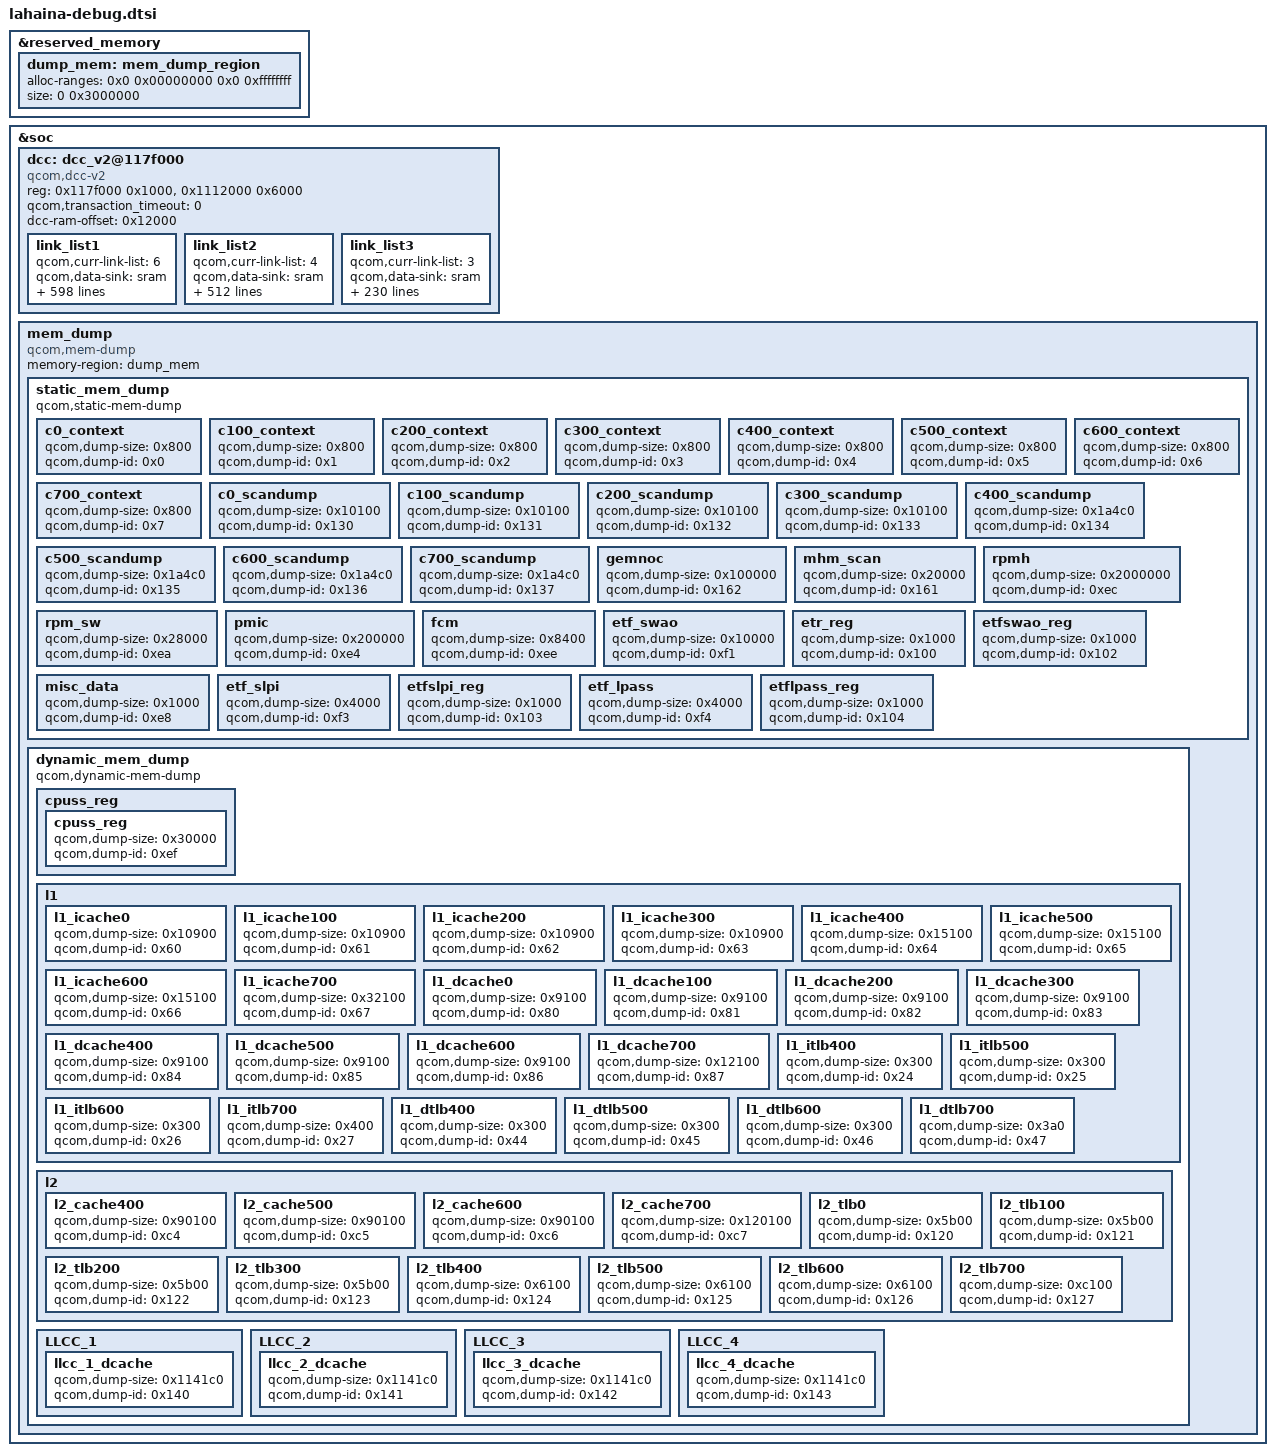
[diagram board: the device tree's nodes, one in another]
// SPDX-License-Identifier: BSD-3-Clause
/*
 * Copyright (c) Qualcomm Technologies, Inc. and/or its subsidiaries.
 */

#include <dt-bindings/soc/qcom,dcc_v2.h>

&reserved_memory {
	#address-cells = <2>;
	#size-cells = <2>;
	ranges;

	dump_mem: mem_dump_region {
		alloc-ranges = <0x0 0x00000000 0x0 0xffffffff>;
		size = <0 0x3000000>;
	};
};

&soc {
	dcc: dcc_v2@117f000 {
		compatible = "qcom,dcc-v2";

		reg = <0x117f000 0x1000>,
			<0x1112000 0x6000>;

		qcom,transaction_timeout = <0>;

		reg-names = "dcc-base", "dcc-ram-base";
		dcc-ram-offset = <0x12000>;

		link_list1 {
			qcom,curr-link-list = <6>;
			qcom,data-sink = "sram";

			qcom,link-list = <DCC_WRITE 0x18080010 0x1 0>,
				<DCC_READ 0x00144018 1 0>,
				<DCC_WRITE 0x00144018 0x1 0>,
				<DCC_READ 0x00144018 1 0>,
				<DCC_READ 0x091a9020 1 0>,
				<DCC_READ_WRITE 0x5 0x1 0>,
				<DCC_READ 0x09102008 1 0>,
				<DCC_READ_WRITE 0x2 0x2 0>,
				<DCC_READ 0x09142008 1 0>,
				<DCC_READ_WRITE 0x2 0x2 0>,
				<DCC_READ 0x09102408 1 0>,
				<DCC_READ_WRITE 0x2 0x2 0>,
				<DCC_READ 0x09142408 1 0>,
				<DCC_READ_WRITE 0x2 0x2 0>,
				<DCC_READ 0x09103808 1 0>,
				<DCC_LOOP 3 0 0>,
				<DCC_READ 0x09103810 1 0>,
				<DCC_READ 0x09103814 1 0>,
				<DCC_LOOP 1 0 0>,
				<DCC_READ 0x09103888 1 0>,
				<DCC_LOOP 2 0 0>,
				<DCC_READ 0x09103890 1 0>,
				<DCC_READ 0x09103894 1 0>,
				<DCC_LOOP 1 0 0>,
				<DCC_READ 0x09143808 1 0>,
				<DCC_LOOP 3 0 0>,
				<DCC_READ 0x09143810 1 0>,
				<DCC_READ 0x09143814 1 0>,
				<DCC_LOOP 1 0 0>,
				<DCC_READ 0x09143888 1 0>,
				<DCC_LOOP 2 0 0>,
				<DCC_READ 0x09143890 1 0>,
				<DCC_READ 0x09143894 1 0>,
				<DCC_LOOP 1 0 0>,
				<DCC_READ 0x09182808 1 0>,
				<DCC_LOOP 2 0 0>,
				<DCC_READ 0x09182810 1 0>,
				<DCC_READ 0x09182814 1 0>,
				<DCC_LOOP 1 0 0>,
				<DCC_READ 0x09182888 1 0>,
				<DCC_LOOP 3 0 0>,
				<DCC_READ 0x09182890 1 0>,
				<DCC_READ 0x09182894 1 0>,
				<DCC_LOOP 1 0 0>,
				<DCC_READ 0x09103008 1 0>,
				<DCC_READ 0x0910300c 1 0>,
				<DCC_WRITE 0x09103028 0x00000001 1>,
				<DCC_LOOP 41 0 0>,
				<DCC_READ 0x09103010 1 0>,
				<DCC_READ 0x09103014 1 0>,
				<DCC_LOOP 1 0 0>,
				<DCC_READ 0x09103408 1 0>,
				<DCC_READ 0x0910340c 1 0>,
				<DCC_WRITE 0x09103428 0x00000001 1>,
				<DCC_LOOP 41 0 0>,
				<DCC_READ 0x09103410 1 0>,
				<DCC_READ 0x09103414 1 0>,
				<DCC_LOOP 1 0 0>,
				<DCC_READ 0x09143008 1 0>,
				<DCC_READ 0x0914300c 1 0>,
				<DCC_WRITE 0x09143028 0x00000001 1>,
				<DCC_LOOP 41 0 0>,
				<DCC_READ 0x09143010 1 0>,
				<DCC_READ 0x09143014 1 0>,
				<DCC_LOOP 1 0 0>,
				<DCC_READ 0x09143408 1 0>,
				<DCC_READ 0x0914340c 1 0>,
				<DCC_WRITE 0x09143428 0x00000001 1>,
				<DCC_LOOP 41 0 0>,
				<DCC_READ 0x09143410 1 0>,
				<DCC_READ 0x09143414 1 0>,
				<DCC_LOOP 1 0 0>,
				<DCC_READ 0x09182008 1 0>,
				<DCC_READ 0x0918200c 1 0>,
				<DCC_WRITE 0x09182028 0x00000001 1>,
				<DCC_LOOP 11 0 0>,
				<DCC_READ 0x09182010 1 0>,
				<DCC_READ 0x09182014 1 0>,
				<DCC_LOOP 1 0 0>,
				<DCC_READ 0x09182408 1 0>,
				<DCC_READ 0x0918240c 1 0>,
				<DCC_WRITE 0x09182428 0x00000001 1>,
				<DCC_LOOP 11 0 0>,
				<DCC_READ 0x09182410 1 0>,
				<DCC_READ 0x09182414 1 0>,
				<DCC_LOOP 1 0 0>,
				<DCC_READ 0x18000024 1 0>,
				<DCC_READ 0x18000040 4 0>,
				<DCC_READ 0x18010024 1 0>,
				<DCC_READ 0x18010040 4 0>,
				<DCC_READ 0x18020024 1 0>,
				<DCC_READ 0x18020040 4 0>,
				<DCC_READ 0x18030024 1 0>,
				<DCC_READ 0x18030040 4 0>,
				<DCC_READ 0x18040024 1 0>,
				<DCC_READ 0x18040040 4 0>,
				<DCC_READ 0x18050024 1 0>,
				<DCC_READ 0x18050040 4 0>,
				<DCC_READ 0x18060024 1 0>,
				<DCC_READ 0x18060040 4 0>,
				<DCC_READ 0x18070024 1 0>,
				<DCC_READ 0x18070040 4 0>,
				<DCC_READ 0x18080024 1 0>,
				<DCC_READ 0x18080040 3 0>,
				<DCC_READ 0x180800f8 1 0>,
				<DCC_READ 0x18080104 1 0>,
				<DCC_READ 0x1808011c 1 0>,
				<DCC_READ 0x18080128 1 0>,
				<DCC_READ 0x18080168 1 0>,
				<DCC_READ 0x18080198 1 0>,
				<DCC_READ 0x9050078 1 0>,
				<DCC_READ 0x9050110 8 0>,
				<DCC_READ 0x9080058 2 0>,
				<DCC_READ 0x90800c8 1 0>,
				<DCC_READ 0x90800d4 1 0>,
				<DCC_READ 0x90800e0 1 0>,
				<DCC_READ 0x90800ec 1 0>,
				<DCC_READ 0x90800f8 1 0>,
				<DCC_READ 0x9084030 1 0>,
				<DCC_READ 0x9084038 2 0>,
				<DCC_READ 0x90840e4 1 0>,
				<DCC_READ 0x90840f4 1 0>,
				<DCC_READ 0x9084104 2 0>,
				<DCC_READ 0x9084194 1 0>,
				<DCC_READ 0x9084804 1 0>,
				<DCC_READ 0x908480c 1 0>,
				<DCC_READ 0x9084844 1 0>,
				<DCC_READ 0x9084850 2 0>,
				<DCC_READ 0x9084860 3 0>,
				<DCC_READ 0x9084888 1 0>,
				<DCC_READ 0x908488c 1 0>,
				<DCC_READ 0x9084900 1 0>,
				<DCC_READ 0x908409c 1 0>,
				<DCC_READ 0x90840a0 1 0>,
				<DCC_READ 0x908426c 1 0>,
				<DCC_READ 0x908439c 1 0>,
				<DCC_READ 0x9085124 1 0>,
				<DCC_READ 0x90ba280 1 0>,
				<DCC_READ 0x90ba288 7 0>,
				<DCC_READ 0x9258610 4 0>,
				<DCC_READ 0x92d8610 4 0>,
				<DCC_READ 0x9358610 4 0>,
				<DCC_READ 0x93d8610 4 0>,
				<DCC_READ 0x9220344 8 0>,
				<DCC_READ 0x9220370 6 0>,
				<DCC_READ 0x9220480 1 0>,
				<DCC_READ 0x9222400 1 0>,
				<DCC_READ 0x922240c 1 0>,
				<DCC_READ 0x9223214 2 0>,
				<DCC_READ 0x9223220 3 0>,
				<DCC_READ 0x9223308 1 0>,
				<DCC_READ 0x9223318 1 0>,
				<DCC_READ 0x9232100 1 0>,
				<DCC_READ 0x9236040 6 0>,
				<DCC_READ 0x92360b0 1 0>,
				<DCC_READ 0x923a004 4 0>,
				<DCC_READ 0x923e030 2 0>,
				<DCC_READ 0x9241000 1 0>,
				<DCC_READ 0x9242028 1 0>,
				<DCC_READ 0x9242044 3 0>,
				<DCC_READ 0x9242070 1 0>,
				<DCC_READ 0x9248030 1 0>,
				<DCC_READ 0x9248048 8 0>,
				<DCC_READ 0x92a0344 8 0>,
				<DCC_READ 0x92a0370 6 0>,
				<DCC_READ 0x92a0480 1 0>,
				<DCC_READ 0x92a2400 1 0>,
				<DCC_READ 0x92a240c 1 0>,
				<DCC_READ 0x92a3214 2 0>,
				<DCC_READ 0x92a3220 3 0>,
				<DCC_READ 0x92a3308 1 0>,
				<DCC_READ 0x92a3318 1 0>,
				<DCC_READ 0x92b2100 1 0>,
				<DCC_READ 0x92b6040 6 0>,
				<DCC_READ 0x92b60b0 1 0>,
				<DCC_READ 0x92ba004 4 0>,
				<DCC_READ 0x92be030 2 0>,
				<DCC_READ 0x92c1000 1 0>,
				<DCC_READ 0x92c2028 1 0>,
				<DCC_READ 0x92c2044 3 0>,
				<DCC_READ 0x92c2070 1 0>,
				<DCC_READ 0x92c8030 1 0>,
				<DCC_READ 0x92c8048 8 0>,
				<DCC_READ 0x9320344 8 0>,
				<DCC_READ 0x9320370 6 0>,
				<DCC_READ 0x9320480 1 0>,
				<DCC_READ 0x9322400 1 0>,
				<DCC_READ 0x932240c 1 0>,
				<DCC_READ 0x9323214 2 0>,
				<DCC_READ 0x9323220 3 0>,
				<DCC_READ 0x9323308 1 0>,
				<DCC_READ 0x9323318 1 0>,
				<DCC_READ 0x9332100 1 0>,
				<DCC_READ 0x9336040 6 0>,
				<DCC_READ 0x93360b0 1 0>,
				<DCC_READ 0x933a004 4 0>,
				<DCC_READ 0x933e030 2 0>,
				<DCC_READ 0x9341000 1 0>,
				<DCC_READ 0x9342028 1 0>,
				<DCC_READ 0x9342044 3 0>,
				<DCC_READ 0x9342070 1 0>,
				<DCC_READ 0x9348030 1 0>,
				<DCC_READ 0x9348048 8 0>,
				<DCC_READ 0x93a0344 8 0>,
				<DCC_READ 0x93a0370 6 0>,
				<DCC_READ 0x93a0480 1 0>,
				<DCC_READ 0x93a2400 1 0>,
				<DCC_READ 0x93a240c 1 0>,
				<DCC_READ 0x93a3214 2 0>,
				<DCC_READ 0x93a3220 3 0>,
				<DCC_READ 0x93a3308 1 0>,
				<DCC_READ 0x93a3318 1 0>,
				<DCC_READ 0x93b2100 1 0>,
				<DCC_READ 0x93b6040 6 0>,
				<DCC_READ 0x93b60b0 1 0>,
				<DCC_READ 0x93ba004 4 0>,
				<DCC_READ 0x93be030 2 0>,
				<DCC_READ 0x93c1000 1 0>,
				<DCC_READ 0x93c2028 1 0>,
				<DCC_READ 0x93c2044 3 0>,
				<DCC_READ 0x93c2070 1 0>,
				<DCC_READ 0x93c8030 1 0>,
				<DCC_READ 0x93c8048 8 0>,
				<DCC_READ 0x9270080 1 0>,
				<DCC_READ 0x9270310 1 0>,
				<DCC_READ 0x9270400 1 0>,
				<DCC_READ 0x9270410 6 0>,
				<DCC_READ 0x9270430 1 0>,
				<DCC_READ 0x9270440 1 0>,
				<DCC_READ 0x9270448 1 0>,
				<DCC_READ 0x92704a0 1 0>,
				<DCC_READ 0x92704b0 1 0>,
				<DCC_READ 0x92704b8 2 0>,
				<DCC_READ 0x92704d0 2 0>,
				<DCC_READ 0x9271400 1 0>,
				<DCC_READ 0x9271408 1 0>,
				<DCC_READ 0x927341c 1 0>,
				<DCC_READ 0x92753b0 1 0>,
				<DCC_READ 0x9275804 1 0>,
				<DCC_READ 0x9275c1c 1 0>,
				<DCC_READ 0x9275c2c 1 0>,
				<DCC_READ 0x9275c38 1 0>,
				<DCC_READ 0x9276418 2 0>,
				<DCC_READ 0x9279100 1 0>,
				<DCC_READ 0x9279110 1 0>,
				<DCC_READ 0x9279120 1 0>,
				<DCC_READ 0x9279180 2 0>,
				<DCC_READ 0x92f0080 1 0>,
				<DCC_READ 0x92f0310 1 0>,
				<DCC_READ 0x92f0400 1 0>,
				<DCC_READ 0x92f0410 6 0>,
				<DCC_READ 0x92f0430 1 0>,
				<DCC_READ 0x92f0440 1 0>,
				<DCC_READ 0x92f0448 1 0>,
				<DCC_READ 0x92f04a0 1 0>,
				<DCC_READ 0x92f04b0 1 0>,
				<DCC_READ 0x92f04b8 2 0>,
				<DCC_READ 0x92f04d0 2 0>,
				<DCC_READ 0x92f1400 1 0>,
				<DCC_READ 0x92f1408 1 0>,
				<DCC_READ 0x92f341c 1 0>,
				<DCC_READ 0x92f53b0 1 0>,
				<DCC_READ 0x92f5804 1 0>,
				<DCC_READ 0x92f5c1c 1 0>,
				<DCC_READ 0x92f5c2c 1 0>,
				<DCC_READ 0x92f5c38 1 0>,
				<DCC_READ 0x92f6418 2 0>,
				<DCC_READ 0x92f9100 1 0>,
				<DCC_READ 0x92f9110 1 0>,
				<DCC_READ 0x92f9120 1 0>,
				<DCC_READ 0x92f9180 2 0>,
				<DCC_READ 0x9370080 1 0>,
				<DCC_READ 0x9370310 1 0>,
				<DCC_READ 0x9370400 1 0>,
				<DCC_READ 0x9370410 6 0>,
				<DCC_READ 0x9370430 1 0>,
				<DCC_READ 0x9370440 1 0>,
				<DCC_READ 0x9370448 1 0>,
				<DCC_READ 0x93704a0 1 0>,
				<DCC_READ 0x93704b0 1 0>,
				<DCC_READ 0x93704b8 2 0>,
				<DCC_READ 0x93704d0 2 0>,
				<DCC_READ 0x9371400 1 0>,
				<DCC_READ 0x9371408 1 0>,
				<DCC_READ 0x937341c 1 0>,
				<DCC_READ 0x93753b0 1 0>,
				<DCC_READ 0x9375804 1 0>,
				<DCC_READ 0x9375c1c 1 0>,
				<DCC_READ 0x9375c2c 1 0>,
				<DCC_READ 0x9375c38 1 0>,
				<DCC_READ 0x9376418 2 0>,
				<DCC_READ 0x9379100 1 0>,
				<DCC_READ 0x9379110 1 0>,
				<DCC_READ 0x9379120 1 0>,
				<DCC_READ 0x9379180 2 0>,
				<DCC_READ 0x93f0080 1 0>,
				<DCC_READ 0x93f0310 1 0>,
				<DCC_READ 0x93f0400 1 0>,
				<DCC_READ 0x93f0410 6 0>,
				<DCC_READ 0x93f0430 1 0>,
				<DCC_READ 0x93f0440 1 0>,
				<DCC_READ 0x93f0448 1 0>,
				<DCC_READ 0x93f04a0 1 0>,
				<DCC_READ 0x93f04b0 1 0>,
				<DCC_READ 0x93f04b8 2 0>,
				<DCC_READ 0x93f04d0 2 0>,
				<DCC_READ 0x93f1400 1 0>,
				<DCC_READ 0x93f1408 1 0>,
				<DCC_READ 0x93f341c 1 0>,
				<DCC_READ 0x93f53b0 1 0>,
				<DCC_READ 0x93f5804 1 0>,
				<DCC_READ 0x93f5c1c 1 0>,
				<DCC_READ 0x93f5c2c 1 0>,
				<DCC_READ 0x93f5c38 1 0>,
				<DCC_READ 0x93f6418 2 0>,
				<DCC_READ 0x93f9100 1 0>,
				<DCC_READ 0x93f9110 1 0>,
				<DCC_READ 0x93f9120 1 0>,
				<DCC_READ 0x93f9180 2 0>,
				<DCC_READ 0x9260080 1 0>,
				<DCC_READ 0x9260400 1 0>,
				<DCC_READ 0x9260410 3 0>,
				<DCC_READ 0x9260420 2 0>,
				<DCC_READ 0x9260430 1 0>,
				<DCC_READ 0x9260440 1 0>,
				<DCC_READ 0x9260448 1 0>,
				<DCC_READ 0x92604a0 1 0>,
				<DCC_READ 0x92604b0 1 0>,
				<DCC_READ 0x92604b8 2 0>,
				<DCC_READ 0x92604d0 2 0>,
				<DCC_READ 0x9261400 1 0>,
				<DCC_READ 0x9263410 1 0>,
				<DCC_READ 0x92653b0 1 0>,
				<DCC_READ 0x9265804 1 0>,
				<DCC_READ 0x9265b1c 1 0>,
				<DCC_READ 0x9265b2c 1 0>,
				<DCC_READ 0x9265b38 1 0>,
				<DCC_READ 0x9269100 1 0>,
				<DCC_READ 0x9269108 1 0>,
				<DCC_READ 0x9269110 1 0>,
				<DCC_READ 0x9269118 1 0>,
				<DCC_READ 0x9269120 1 0>,
				<DCC_READ 0x9269180 2 0>,
				<DCC_READ 0x92e0080 1 0>,
				<DCC_READ 0x92e0400 1 0>,
				<DCC_READ 0x92e0410 3 0>,
				<DCC_READ 0x92e0420 2 0>,
				<DCC_READ 0x92e0430 1 0>,
				<DCC_READ 0x92e0440 1 0>,
				<DCC_READ 0x92e0448 1 0>,
				<DCC_READ 0x92e04a0 1 0>,
				<DCC_READ 0x92e04b0 1 0>,
				<DCC_READ 0x92e04b8 2 0>,
				<DCC_READ 0x92e04d0 2 0>,
				<DCC_READ 0x92e1400 1 0>,
				<DCC_READ 0x92e3410 1 0>,
				<DCC_READ 0x92e53b0 1 0>,
				<DCC_READ 0x92e5804 1 0>,
				<DCC_READ 0x92e5b1c 1 0>,
				<DCC_READ 0x92e5b2c 1 0>,
				<DCC_READ 0x92e5b38 1 0>,
				<DCC_READ 0x92e9100 1 0>,
				<DCC_READ 0x92e9108 1 0>,
				<DCC_READ 0x92e9110 1 0>,
				<DCC_READ 0x92e9118 1 0>,
				<DCC_READ 0x92e9120 1 0>,
				<DCC_READ 0x92e9180 2 0>,
				<DCC_READ 0x9360080 1 0>,
				<DCC_READ 0x9360400 1 0>,
				<DCC_READ 0x9360410 3 0>,
				<DCC_READ 0x9360420 2 0>,
				<DCC_READ 0x9360430 1 0>,
				<DCC_READ 0x9360440 1 0>,
				<DCC_READ 0x9360448 1 0>,
				<DCC_READ 0x93604a0 1 0>,
				<DCC_READ 0x93604b0 1 0>,
				<DCC_READ 0x93604b8 2 0>,
				<DCC_READ 0x93604d0 2 0>,
				<DCC_READ 0x9361400 1 0>,
				<DCC_READ 0x9363410 1 0>,
				<DCC_READ 0x93653b0 1 0>,
				<DCC_READ 0x9365804 1 0>,
				<DCC_READ 0x9365b1c 1 0>,
				<DCC_READ 0x9365b2c 1 0>,
				<DCC_READ 0x9365b38 1 0>,
				<DCC_READ 0x9369100 1 0>,
				<DCC_READ 0x9369108 1 0>,
				<DCC_READ 0x9369110 1 0>,
				<DCC_READ 0x9369118 1 0>,
				<DCC_READ 0x9369120 1 0>,
				<DCC_READ 0x9369180 2 0>,
				<DCC_READ 0x93e0080 1 0>,
				<DCC_READ 0x93e0400 1 0>,
				<DCC_READ 0x93e0410 3 0>,
				<DCC_READ 0x93e0420 2 0>,
				<DCC_READ 0x93e0430 1 0>,
				<DCC_READ 0x93e0440 1 0>,
				<DCC_READ 0x93e0448 1 0>,
				<DCC_READ 0x93e04a0 1 0>,
				<DCC_READ 0x93e04b0 1 0>,
				<DCC_READ 0x93e04b8 2 0>,
				<DCC_READ 0x93e04d0 2 0>,
				<DCC_READ 0x93e1400 1 0>,
				<DCC_READ 0x93e3410 1 0>,
				<DCC_READ 0x93e53b0 1 0>,
				<DCC_READ 0x93e5804 1 0>,
				<DCC_READ 0x93e5b1c 1 0>,
				<DCC_READ 0x93e5b2c 1 0>,
				<DCC_READ 0x93e5b38 1 0>,
				<DCC_READ 0x93e9100 1 0>,
				<DCC_READ 0x93e9108 1 0>,
				<DCC_READ 0x93e9110 1 0>,
				<DCC_READ 0x93e9118 1 0>,
				<DCC_READ 0x93e9120 1 0>,
				<DCC_READ 0x93e9180 2 0>,
				<DCC_READ 0x96b0868 1 0>,
				<DCC_READ 0x96b0870 1 0>,
				<DCC_READ 0x96b1004 1 0>,
				<DCC_READ 0x96b100c 1 0>,
				<DCC_READ 0x96b1014 1 0>,
				<DCC_READ 0x96b1204 1 0>,
				<DCC_READ 0x96b120c 1 0>,
				<DCC_READ 0x96b1214 1 0>,
				<DCC_READ 0x96b1504 1 0>,
				<DCC_READ 0x96b150c 1 0>,
				<DCC_READ 0x96b1514 1 0>,
				<DCC_READ 0x96b1604 1 0>,
				<DCC_READ 0x96b8100 1 0>,
				<DCC_READ 0x96b813c 1 0>,
				<DCC_READ 0x96b8500 1 0>,
				<DCC_READ 0x96b853c 1 0>,
				<DCC_READ 0x96b8a04 1 0>,
				<DCC_READ 0x96b8a18 1 0>,
				<DCC_READ 0x96b8ea8 1 0>,
				<DCC_READ 0x96b9044 1 0>,
				<DCC_READ 0x96b904c 1 0>,
				<DCC_READ 0x96b9054 1 0>,
				<DCC_READ 0x96b905c 1 0>,
				<DCC_READ 0x96b910c 2 0>,
				<DCC_READ 0x96b9204 1 0>,
				<DCC_READ 0x96b920c 1 0>,
				<DCC_READ 0x96b9238 1 0>,
				<DCC_READ 0x96b9240 1 0>,
				<DCC_READ 0x96b926c 1 0>,
				<DCC_READ 0x96b9394 1 0>,
				<DCC_READ 0x96b939c 1 0>,
				<DCC_READ 0x96b9704 1 0>,
				<DCC_READ 0x96b970c 1 0>,
				<DCC_READ 0x96f0868 1 0>,
				<DCC_READ 0x96f0870 1 0>,
				<DCC_READ 0x96f1004 1 0>,
				<DCC_READ 0x96f100c 1 0>,
				<DCC_READ 0x96f1014 1 0>,
				<DCC_READ 0x96f1204 1 0>,
				<DCC_READ 0x96f120c 1 0>,
				<DCC_READ 0x96f1214 1 0>,
				<DCC_READ 0x96f1504 1 0>,
				<DCC_READ 0x96f150c 1 0>,
				<DCC_READ 0x96f1514 1 0>,
				<DCC_READ 0x96f1604 1 0>,
				<DCC_READ 0x96f8100 1 0>,
				<DCC_READ 0x96f813c 1 0>,
				<DCC_READ 0x96f8500 1 0>,
				<DCC_READ 0x96f853c 1 0>,
				<DCC_READ 0x96f8a04 1 0>,
				<DCC_READ 0x96f8a18 1 0>,
				<DCC_READ 0x96f8ea8 1 0>,
				<DCC_READ 0x96f9044 1 0>,
				<DCC_READ 0x96f904c 1 0>,
				<DCC_READ 0x96f9054 1 0>,
				<DCC_READ 0x96f905c 1 0>,
				<DCC_READ 0x96f910c 2 0>,
				<DCC_READ 0x96f9204 1 0>,
				<DCC_READ 0x96f920c 1 0>,
				<DCC_READ 0x96f9238 1 0>,
				<DCC_READ 0x96f9240 1 0>,
				<DCC_READ 0x96f926c 1 0>,
				<DCC_READ 0x96f9394 1 0>,
				<DCC_READ 0x96f939c 1 0>,
				<DCC_READ 0x96f9704 1 0>,
				<DCC_READ 0x96f970c 1 0>,
				<DCC_READ 0x9730868 1 0>,
				<DCC_READ 0x9730870 1 0>,
				<DCC_READ 0x9731004 1 0>,
				<DCC_READ 0x973100c 1 0>,
				<DCC_READ 0x9731014 1 0>,
				<DCC_READ 0x9731204 1 0>,
				<DCC_READ 0x973120c 1 0>,
				<DCC_READ 0x9731214 1 0>,
				<DCC_READ 0x9731504 1 0>,
				<DCC_READ 0x973150c 1 0>,
				<DCC_READ 0x9731514 1 0>,
				<DCC_READ 0x9731604 1 0>,
				<DCC_READ 0x9738100 1 0>,
				<DCC_READ 0x973813c 1 0>,
				<DCC_READ 0x9738500 1 0>,
				<DCC_READ 0x973853c 1 0>,
				<DCC_READ 0x9738a04 1 0>,
				<DCC_READ 0x9738a18 1 0>,
				<DCC_READ 0x9738ea8 1 0>,
				<DCC_READ 0x9739044 1 0>,
				<DCC_READ 0x973904c 1 0>,
				<DCC_READ 0x9739054 1 0>,
				<DCC_READ 0x973905c 1 0>,
				<DCC_READ 0x973910c 2 0>,
				<DCC_READ 0x9739204 1 0>,
				<DCC_READ 0x973920c 1 0>,
				<DCC_READ 0x9739238 1 0>,
				<DCC_READ 0x9739240 1 0>,
				<DCC_READ 0x973926c 1 0>,
				<DCC_READ 0x9739394 1 0>,
				<DCC_READ 0x973939c 1 0>,
				<DCC_READ 0x9739704 1 0>,
				<DCC_READ 0x973970c 1 0>,
				<DCC_READ 0x9770868 1 0>,
				<DCC_READ 0x9770870 1 0>,
				<DCC_READ 0x9771004 1 0>,
				<DCC_READ 0x977100c 1 0>,
				<DCC_READ 0x9771014 1 0>,
				<DCC_READ 0x9771204 1 0>,
				<DCC_READ 0x977120c 1 0>,
				<DCC_READ 0x9771214 1 0>,
				<DCC_READ 0x9771504 1 0>,
				<DCC_READ 0x977150c 1 0>,
				<DCC_READ 0x9771514 1 0>,
				<DCC_READ 0x9771604 1 0>,
				<DCC_READ 0x9778100 1 0>,
				<DCC_READ 0x977813c 1 0>,
				<DCC_READ 0x9778500 1 0>,
				<DCC_READ 0x977853c 1 0>,
				<DCC_READ 0x9778a04 1 0>,
				<DCC_READ 0x9778a18 1 0>,
				<DCC_READ 0x9778ea8 1 0>,
				<DCC_READ 0x9779044 1 0>,
				<DCC_READ 0x977904c 1 0>,
				<DCC_READ 0x9779054 1 0>,
				<DCC_READ 0x977905c 1 0>,
				<DCC_READ 0x977910c 2 0>,
				<DCC_READ 0x9779204 1 0>,
				<DCC_READ 0x977920c 1 0>,
				<DCC_READ 0x9779238 1 0>,
				<DCC_READ 0x9779240 1 0>,
				<DCC_READ 0x977926c 1 0>,
				<DCC_READ 0x9779394 1 0>,
				<DCC_READ 0x977939c 1 0>,
				<DCC_READ 0x9779704 1 0>,
				<DCC_READ 0x977970c 1 0>,
				<DCC_READ 0x910d100 3 0>,
				<DCC_READ 0x914d100 3 0>,
				<DCC_READ 0x918d100 4 0>,
				<DCC_READ 0x91a5100 1 0>,
				<DCC_READ 0x91ad100 1 0>,
				<DCC_READ 0x610110 5 0>,
				<DCC_WRITE 0x06e0a00c 0x00600007 1>,
				<DCC_WRITE 0x06e0a01c 0x00136800 1>,
				<DCC_READ 0x06e0a014 1 1>,
				<DCC_WRITE 0x06e0a01c 0x00136810 1>,
				<DCC_READ 0x06e0a014 1 1>,
				<DCC_WRITE 0x06e0a01c 0x00136820 1>,
				<DCC_READ 0x06e0a014 1 1>,
				<DCC_WRITE 0x06e0a01c 0x00136830 1>,
				<DCC_READ 0x06e0a014 1 1>,
				<DCC_WRITE 0x06e0a01c 0x00136840 1>,
				<DCC_READ 0x06e0a014 1 1>,
				<DCC_WRITE 0x06e0a01c 0x00136850 1>,
				<DCC_READ 0x06e0a014 1 1>,
				<DCC_WRITE 0x06e0a01c 0x00136860 1>,
				<DCC_READ 0x06e0a014 1 1>,
				<DCC_WRITE 0x06e0a01c 0x00136870 1>,
				<DCC_READ 0x06e0a014 1 1>,
				<DCC_WRITE 0x06e0a01c 0x0003e9a0 1>,
				<DCC_WRITE 0x06e0a01c 0x001368a0 1>,
				<DCC_READ 0x06e0a014 1 1>,
				<DCC_WRITE 0x06e0a01c 0x0003c0a0 1>,
				<DCC_WRITE 0x06e0a01c 0x001368a0 1>,
				<DCC_READ 0x06e0a014 1 1>,
				<DCC_WRITE 0x06e0a01c 0x0003d1a0 1>,
				<DCC_WRITE 0x06e0a01c 0x001368a0 1>,
				<DCC_READ 0x06e0a014 1 1>,
				<DCC_WRITE 0x06e0a01c 0x0003d2a0 1>,
				<DCC_WRITE 0x06e0a01c 0x001368a0 1>,
				<DCC_READ 0x06e0a014 1 1>,
				<DCC_WRITE 0x06e0a01c 0x0003d5a0 1>,
				<DCC_WRITE 0x06e0a01c 0x001368a0 1>,
				<DCC_READ 0x06e0a014 1 1>,
				<DCC_WRITE 0x06e0a01c 0x0003d6a0 1>,
				<DCC_WRITE 0x06e0a01c 0x001368a0 1>,
				<DCC_READ 0x06e0a014 1 1>,
				<DCC_WRITE 0x06e0a01c 0x0003e8a0 1>,
				<DCC_WRITE 0x06e0a01c 0x001368a0 1>,
				<DCC_READ 0x06e0a014 1 1>,
				<DCC_WRITE 0x06e0a01c 0x0003eea0 1>,
				<DCC_WRITE 0x06e0a01c 0x001368a0 1>,
				<DCC_READ 0x06e0a014 1 1>,
				<DCC_WRITE 0x06e0a01c 0x0003b1a0 1>,
				<DCC_WRITE 0x06e0a01c 0x001368a0 1>,
				<DCC_READ 0x06e0a014 1 1>,
				<DCC_WRITE 0x06e0a01c 0x0003b2a0 1>,
				<DCC_WRITE 0x06e0a01c 0x001368a0 1>,
				<DCC_READ 0x06e0a014 1 1>,
				<DCC_WRITE 0x06e0a01c 0x0003b5a0 1>,
				<DCC_WRITE 0x06e0a01c 0x001368a0 1>,
				<DCC_READ 0x06e0a014 1 1>,
				<DCC_WRITE 0x06e0a01c 0x0003b6a0 1>,
				<DCC_WRITE 0x06e0a01c 0x001368a0 1>,
				<DCC_READ 0x06e0a014 1 1>,
				<DCC_WRITE 0x06e0a01c 0x0003c2a0 1>,
				<DCC_WRITE 0x06e0a01c 0x001368a0 1>,
				<DCC_READ 0x06e0a014 1 1>,
				<DCC_WRITE 0x06e0a01c 0x0003c5a0 1>,
				<DCC_WRITE 0x06e0a01c 0x001368a0 1>,
				<DCC_READ 0x06e0a014 1 1>,
				<DCC_WRITE 0x06e0a01c 0x0003c6a0 1>,
				<DCC_WRITE 0x06e0a01c 0x001368a0 1>,
				<DCC_READ 0x06e0a014 1 1>,
				<DCC_WRITE 0x06e0a014 0x0002000c 1>,
				<DCC_WRITE 0x06e0a01c 0x000368b0 1>,
				<DCC_WRITE 0x06e0a01c 0x00000ba8 1>,
				<DCC_WRITE 0x06e0a01c 0x0013b6a0 1>,
				<DCC_WRITE 0x06e0a01c 0x00f1e000 1>,
				<DCC_WRITE 0x06e0a008 0x00000007 1>,
				<DCC_READ 0x09067e00 124 0>;
		};

		link_list2 {
			qcom,curr-link-list = <4>;
			qcom,data-sink = "sram";

			qcom,link-list = <DCC_READ 0x9050078 1 0>,
				<DCC_READ 0x9050110 8 0>,
				<DCC_READ 0x9080058 2 0>,
				<DCC_READ 0x90800c8 1 0>,
				<DCC_READ 0x90800d4 1 0>,
				<DCC_READ 0x90800e0 1 0>,
				<DCC_READ 0x90800ec 1 0>,
				<DCC_READ 0x90800f8 1 0>,
				<DCC_READ 0x9084030 1 0>,
				<DCC_READ 0x9084038 2 0>,
				<DCC_READ 0x90840e4 1 0>,
				<DCC_READ 0x90840f4 1 0>,
				<DCC_READ 0x9084104 2 0>,
				<DCC_READ 0x9084194 1 0>,
				<DCC_READ 0x9084804 1 0>,
				<DCC_READ 0x908480c 1 0>,
				<DCC_READ 0x9084844 1 0>,
				<DCC_READ 0x9084850 2 0>,
				<DCC_READ 0x9084860 3 0>,
				<DCC_READ 0x9084888 1 0>,
				<DCC_READ 0x908488c 1 0>,
				<DCC_READ 0x9084900 1 0>,
				<DCC_READ 0x908409c 1 0>,
				<DCC_READ 0x90840a0 1 0>,
				<DCC_READ 0x908426c 1 0>,
				<DCC_READ 0x908439c 1 0>,
				<DCC_READ 0x9085124 1 0>,
				<DCC_READ 0x90ba280 1 0>,
				<DCC_READ 0x90ba288 7 0>,
				<DCC_READ 0x9258610 4 0>,
				<DCC_READ 0x92d8610 4 0>,
				<DCC_READ 0x9358610 4 0>,
				<DCC_READ 0x93d8610 4 0>,
				<DCC_READ 0x9220344 8 0>,
				<DCC_READ 0x9220370 6 0>,
				<DCC_READ 0x9220480 1 0>,
				<DCC_READ 0x9222400 1 0>,
				<DCC_READ 0x922240c 1 0>,
				<DCC_READ 0x9223214 2 0>,
				<DCC_READ 0x9223220 3 0>,
				<DCC_READ 0x9223308 1 0>,
				<DCC_READ 0x9223318 1 0>,
				<DCC_READ 0x9232100 1 0>,
				<DCC_READ 0x9236040 6 0>,
				<DCC_READ 0x92360b0 1 0>,
				<DCC_READ 0x923a004 4 0>,
				<DCC_READ 0x923e030 2 0>,
				<DCC_READ 0x9241000 1 0>,
				<DCC_READ 0x9242028 1 0>,
				<DCC_READ 0x9242044 3 0>,
				<DCC_READ 0x9242070 1 0>,
				<DCC_READ 0x9248030 1 0>,
				<DCC_READ 0x9248048 8 0>,
				<DCC_READ 0x92a0344 8 0>,
				<DCC_READ 0x92a0370 6 0>,
				<DCC_READ 0x92a0480 1 0>,
				<DCC_READ 0x92a2400 1 0>,
				<DCC_READ 0x92a240c 1 0>,
				<DCC_READ 0x92a3214 2 0>,
				<DCC_READ 0x92a3220 3 0>,
				<DCC_READ 0x92a3308 1 0>,
				<DCC_READ 0x92a3318 1 0>,
				<DCC_READ 0x92b2100 1 0>,
				<DCC_READ 0x92b6040 6 0>,
				<DCC_READ 0x92b60b0 1 0>,
				<DCC_READ 0x92ba004 4 0>,
				<DCC_READ 0x92be030 2 0>,
				<DCC_READ 0x92c1000 1 0>,
				<DCC_READ 0x92c2028 1 0>,
				<DCC_READ 0x92c2044 3 0>,
				<DCC_READ 0x92c2070 1 0>,
				<DCC_READ 0x92c8030 1 0>,
				<DCC_READ 0x92c8048 8 0>,
				<DCC_READ 0x9320344 8 0>,
				<DCC_READ 0x9320370 6 0>,
				<DCC_READ 0x9320480 1 0>,
				<DCC_READ 0x9322400 1 0>,
				<DCC_READ 0x932240c 1 0>,
				<DCC_READ 0x9323214 2 0>,
				<DCC_READ 0x9323220 3 0>,
				<DCC_READ 0x9323308 1 0>,
				<DCC_READ 0x9323318 1 0>,
				<DCC_READ 0x9332100 1 0>,
				<DCC_READ 0x9336040 6 0>,
				<DCC_READ 0x93360b0 1 0>,
				<DCC_READ 0x933a004 4 0>,
				<DCC_READ 0x933e030 2 0>,
				<DCC_READ 0x9341000 1 0>,
				<DCC_READ 0x9342028 1 0>,
				<DCC_READ 0x9342044 3 0>,
				<DCC_READ 0x9342070 1 0>,
				<DCC_READ 0x9348030 1 0>,
				<DCC_READ 0x9348048 8 0>,
				<DCC_READ 0x93a0344 8 0>,
				<DCC_READ 0x93a0370 6 0>,
				<DCC_READ 0x93a0480 1 0>,
				<DCC_READ 0x93a2400 1 0>,
				<DCC_READ 0x93a240c 1 0>,
				<DCC_READ 0x93a3214 2 0>,
				<DCC_READ 0x93a3220 3 0>,
				<DCC_READ 0x93a3308 1 0>,
				<DCC_READ 0x93a3318 1 0>,
				<DCC_READ 0x93b2100 1 0>,
				<DCC_READ 0x93b6040 6 0>,
				<DCC_READ 0x93b60b0 1 0>,
				<DCC_READ 0x93ba004 4 0>,
				<DCC_READ 0x93be030 2 0>,
				<DCC_READ 0x93c1000 1 0>,
				<DCC_READ 0x93c2028 1 0>,
				<DCC_READ 0x93c2044 3 0>,
				<DCC_READ 0x93c2070 1 0>,
				<DCC_READ 0x93c8030 1 0>,
				<DCC_READ 0x93c8048 8 0>,
				<DCC_READ 0x9270080 1 0>,
				<DCC_READ 0x9270310 1 0>,
				<DCC_READ 0x9270400 1 0>,
				<DCC_READ 0x9270410 6 0>,
				<DCC_READ 0x9270430 1 0>,
				<DCC_READ 0x9270440 1 0>,
				<DCC_READ 0x9270448 1 0>,
				<DCC_READ 0x92704a0 1 0>,
				<DCC_READ 0x92704b0 1 0>,
				<DCC_READ 0x92704b8 2 0>,
				<DCC_READ 0x92704d0 2 0>,
				<DCC_READ 0x9271400 1 0>,
				<DCC_READ 0x9271408 1 0>,
				<DCC_READ 0x927341c 1 0>,
				<DCC_READ 0x92753b0 1 0>,
				<DCC_READ 0x9275804 1 0>,
				<DCC_READ 0x9275c1c 1 0>,
				<DCC_READ 0x9275c2c 1 0>,
				<DCC_READ 0x9275c38 1 0>,
				<DCC_READ 0x9276418 2 0>,
				<DCC_READ 0x9279100 1 0>,
				<DCC_READ 0x9279110 1 0>,
				<DCC_READ 0x9279120 1 0>,
				<DCC_READ 0x9279180 2 0>,
				<DCC_READ 0x92f0080 1 0>,
				<DCC_READ 0x92f0310 1 0>,
				<DCC_READ 0x92f0400 1 0>,
				<DCC_READ 0x92f0410 6 0>,
				<DCC_READ 0x92f0430 1 0>,
				<DCC_READ 0x92f0440 1 0>,
				<DCC_READ 0x92f0448 1 0>,
				<DCC_READ 0x92f04a0 1 0>,
				<DCC_READ 0x92f04b0 1 0>,
				<DCC_READ 0x92f04b8 2 0>,
				<DCC_READ 0x92f04d0 2 0>,
				<DCC_READ 0x92f1400 1 0>,
				<DCC_READ 0x92f1408 1 0>,
				<DCC_READ 0x92f341c 1 0>,
				<DCC_READ 0x92f53b0 1 0>,
				<DCC_READ 0x92f5804 1 0>,
				<DCC_READ 0x92f5c1c 1 0>,
				<DCC_READ 0x92f5c2c 1 0>,
				<DCC_READ 0x92f5c38 1 0>,
				<DCC_READ 0x92f6418 2 0>,
				<DCC_READ 0x92f9100 1 0>,
				<DCC_READ 0x92f9110 1 0>,
				<DCC_READ 0x92f9120 1 0>,
				<DCC_READ 0x92f9180 2 0>,
				<DCC_READ 0x9370080 1 0>,
				<DCC_READ 0x9370310 1 0>,
				<DCC_READ 0x9370400 1 0>,
				<DCC_READ 0x9370410 6 0>,
				<DCC_READ 0x9370430 1 0>,
				<DCC_READ 0x9370440 1 0>,
				<DCC_READ 0x9370448 1 0>,
				<DCC_READ 0x93704a0 1 0>,
				<DCC_READ 0x93704b0 1 0>,
				<DCC_READ 0x93704b8 2 0>,
				<DCC_READ 0x93704d0 2 0>,
				<DCC_READ 0x9371400 1 0>,
				<DCC_READ 0x9371408 1 0>,
				<DCC_READ 0x937341c 1 0>,
				<DCC_READ 0x93753b0 1 0>,
				<DCC_READ 0x9375804 1 0>,
				<DCC_READ 0x9375c1c 1 0>,
				<DCC_READ 0x9375c2c 1 0>,
				<DCC_READ 0x9375c38 1 0>,
				<DCC_READ 0x9376418 2 0>,
				<DCC_READ 0x9379100 1 0>,
				<DCC_READ 0x9379110 1 0>,
				<DCC_READ 0x9379120 1 0>,
				<DCC_READ 0x9379180 2 0>,
				<DCC_READ 0x93f0080 1 0>,
				<DCC_READ 0x93f0310 1 0>,
				<DCC_READ 0x93f0400 1 0>,
				<DCC_READ 0x93f0410 6 0>,
				<DCC_READ 0x93f0430 1 0>,
				<DCC_READ 0x93f0440 1 0>,
				<DCC_READ 0x93f0448 1 0>,
				<DCC_READ 0x93f04a0 1 0>,
				<DCC_READ 0x93f04b0 1 0>,
				<DCC_READ 0x93f04b8 2 0>,
				<DCC_READ 0x93f04d0 2 0>,
				<DCC_READ 0x93f1400 1 0>,
				<DCC_READ 0x93f1408 1 0>,
				<DCC_READ 0x93f341c 1 0>,
				<DCC_READ 0x93f53b0 1 0>,
				<DCC_READ 0x93f5804 1 0>,
				<DCC_READ 0x93f5c1c 1 0>,
				<DCC_READ 0x93f5c2c 1 0>,
				<DCC_READ 0x93f5c38 1 0>,
				<DCC_READ 0x93f6418 2 0>,
				<DCC_READ 0x93f9100 1 0>,
				<DCC_READ 0x93f9110 1 0>,
				<DCC_READ 0x93f9120 1 0>,
				<DCC_READ 0x93f9180 2 0>,
				<DCC_READ 0x9260080 1 0>,
				<DCC_READ 0x9260400 1 0>,
				<DCC_READ 0x9260410 3 0>,
				<DCC_READ 0x9260420 2 0>,
				<DCC_READ 0x9260430 1 0>,
				<DCC_READ 0x9260440 1 0>,
				<DCC_READ 0x9260448 1 0>,
				<DCC_READ 0x92604a0 1 0>,
				<DCC_READ 0x92604b0 1 0>,
				<DCC_READ 0x92604b8 2 0>,
				<DCC_READ 0x92604d0 2 0>,
				<DCC_READ 0x9261400 1 0>,
				<DCC_READ 0x9263410 1 0>,
				<DCC_READ 0x92653b0 1 0>,
				<DCC_READ 0x9265804 1 0>,
				<DCC_READ 0x9265b1c 1 0>,
				<DCC_READ 0x9265b2c 1 0>,
				<DCC_READ 0x9265b38 1 0>,
				<DCC_READ 0x9269100 1 0>,
				<DCC_READ 0x9269108 1 0>,
				<DCC_READ 0x9269110 1 0>,
				<DCC_READ 0x9269118 1 0>,
				<DCC_READ 0x9269120 1 0>,
				<DCC_READ 0x9269180 2 0>,
				<DCC_READ 0x92e0080 1 0>,
				<DCC_READ 0x92e0400 1 0>,
				<DCC_READ 0x92e0410 3 0>,
				<DCC_READ 0x92e0420 2 0>,
				<DCC_READ 0x92e0430 1 0>,
				<DCC_READ 0x92e0440 1 0>,
				<DCC_READ 0x92e0448 1 0>,
				<DCC_READ 0x92e04a0 1 0>,
				<DCC_READ 0x92e04b0 1 0>,
				<DCC_READ 0x92e04b8 2 0>,
				<DCC_READ 0x92e04d0 2 0>,
				<DCC_READ 0x92e1400 1 0>,
				<DCC_READ 0x92e3410 1 0>,
				<DCC_READ 0x92e53b0 1 0>,
				<DCC_READ 0x92e5804 1 0>,
				<DCC_READ 0x92e5b1c 1 0>,
				<DCC_READ 0x92e5b2c 1 0>,
				<DCC_READ 0x92e5b38 1 0>,
				<DCC_READ 0x92e9100 1 0>,
				<DCC_READ 0x92e9108 1 0>,
				<DCC_READ 0x92e9110 1 0>,
				<DCC_READ 0x92e9118 1 0>,
				<DCC_READ 0x92e9120 1 0>,
				<DCC_READ 0x92e9180 2 0>,
				<DCC_READ 0x9360080 1 0>,
				<DCC_READ 0x9360400 1 0>,
				<DCC_READ 0x9360410 3 0>,
				<DCC_READ 0x9360420 2 0>,
				<DCC_READ 0x9360430 1 0>,
				<DCC_READ 0x9360440 1 0>,
				<DCC_READ 0x9360448 1 0>,
				<DCC_READ 0x93604a0 1 0>,
				<DCC_READ 0x93604b0 1 0>,
				<DCC_READ 0x93604b8 2 0>,
				<DCC_READ 0x93604d0 2 0>,
				<DCC_READ 0x9361400 1 0>,
				<DCC_READ 0x9363410 1 0>,
				<DCC_READ 0x93653b0 1 0>,
				<DCC_READ 0x9365804 1 0>,
				<DCC_READ 0x9365b1c 1 0>,
				<DCC_READ 0x9365b2c 1 0>,
				<DCC_READ 0x9365b38 1 0>,
				<DCC_READ 0x9369100 1 0>,
				<DCC_READ 0x9369108 1 0>,
				<DCC_READ 0x9369110 1 0>,
				<DCC_READ 0x9369118 1 0>,
				<DCC_READ 0x9369120 1 0>,
				<DCC_READ 0x9369180 2 0>,
				<DCC_READ 0x93e0080 1 0>,
				<DCC_READ 0x93e0400 1 0>,
				<DCC_READ 0x93e0410 3 0>,
				<DCC_READ 0x93e0420 2 0>,
				<DCC_READ 0x93e0430 1 0>,
				<DCC_READ 0x93e0440 1 0>,
				<DCC_READ 0x93e0448 1 0>,
				<DCC_READ 0x93e04a0 1 0>,
				<DCC_READ 0x93e04b0 1 0>,
				<DCC_READ 0x93e04b8 2 0>,
				<DCC_READ 0x93e04d0 2 0>,
				<DCC_READ 0x93e1400 1 0>,
				<DCC_READ 0x93e3410 1 0>,
				<DCC_READ 0x93e53b0 1 0>,
				<DCC_READ 0x93e5804 1 0>,
				<DCC_READ 0x93e5b1c 1 0>,
				<DCC_READ 0x93e5b2c 1 0>,
				<DCC_READ 0x93e5b38 1 0>,
				<DCC_READ 0x93e9100 1 0>,
				<DCC_READ 0x93e9108 1 0>,
				<DCC_READ 0x93e9110 1 0>,
				<DCC_READ 0x93e9118 1 0>,
				<DCC_READ 0x93e9120 1 0>,
				<DCC_READ 0x93e9180 2 0>,
				<DCC_READ 0x96b0868 1 0>,
				<DCC_READ 0x96b0870 1 0>,
				<DCC_READ 0x96b1004 1 0>,
				<DCC_READ 0x96b100c 1 0>,
				<DCC_READ 0x96b1014 1 0>,
				<DCC_READ 0x96b1204 1 0>,
				<DCC_READ 0x96b120c 1 0>,
				<DCC_READ 0x96b1214 1 0>,
				<DCC_READ 0x96b1504 1 0>,
				<DCC_READ 0x96b150c 1 0>,
				<DCC_READ 0x96b1514 1 0>,
				<DCC_READ 0x96b1604 1 0>,
				<DCC_READ 0x96b8100 1 0>,
				<DCC_READ 0x96b813c 1 0>,
				<DCC_READ 0x96b8500 1 0>,
				<DCC_READ 0x96b853c 1 0>,
				<DCC_READ 0x96b8a04 1 0>,
				<DCC_READ 0x96b8a18 1 0>,
				<DCC_READ 0x96b8ea8 1 0>,
				<DCC_READ 0x96b9044 1 0>,
				<DCC_READ 0x96b904c 1 0>,
				<DCC_READ 0x96b9054 1 0>,
				<DCC_READ 0x96b905c 1 0>,
				<DCC_READ 0x96b910c 2 0>,
				<DCC_READ 0x96b9204 1 0>,
				<DCC_READ 0x96b920c 1 0>,
				<DCC_READ 0x96b9238 1 0>,
				<DCC_READ 0x96b9240 1 0>,
				<DCC_READ 0x96b926c 1 0>,
				<DCC_READ 0x96b9394 1 0>,
				<DCC_READ 0x96b939c 1 0>,
				<DCC_READ 0x96b9704 1 0>,
				<DCC_READ 0x96b970c 1 0>,
				<DCC_READ 0x96f0868 1 0>,
				<DCC_READ 0x96f0870 1 0>,
				<DCC_READ 0x96f1004 1 0>,
				<DCC_READ 0x96f100c 1 0>,
				<DCC_READ 0x96f1014 1 0>,
				<DCC_READ 0x96f1204 1 0>,
				<DCC_READ 0x96f120c 1 0>,
				<DCC_READ 0x96f1214 1 0>,
				<DCC_READ 0x96f1504 1 0>,
				<DCC_READ 0x96f150c 1 0>,
				<DCC_READ 0x96f1514 1 0>,
				<DCC_READ 0x96f1604 1 0>,
				<DCC_READ 0x96f8100 1 0>,
				<DCC_READ 0x96f813c 1 0>,
				<DCC_READ 0x96f8500 1 0>,
				<DCC_READ 0x96f853c 1 0>,
				<DCC_READ 0x96f8a04 1 0>,
				<DCC_READ 0x96f8a18 1 0>,
				<DCC_READ 0x96f8ea8 1 0>,
				<DCC_READ 0x96f9044 1 0>,
				<DCC_READ 0x96f904c 1 0>,
				<DCC_READ 0x96f9054 1 0>,
				<DCC_READ 0x96f905c 1 0>,
				<DCC_READ 0x96f910c 2 0>,
				<DCC_READ 0x96f9204 1 0>,
				<DCC_READ 0x96f920c 1 0>,
				<DCC_READ 0x96f9238 1 0>,
				<DCC_READ 0x96f9240 1 0>,
				<DCC_READ 0x96f926c 1 0>,
				<DCC_READ 0x96f9394 1 0>,
				<DCC_READ 0x96f939c 1 0>,
				<DCC_READ 0x96f9704 1 0>,
				<DCC_READ 0x96f970c 1 0>,
				<DCC_READ 0x9730868 1 0>,
				<DCC_READ 0x9730870 1 0>,
				<DCC_READ 0x9731004 1 0>,
				<DCC_READ 0x973100c 1 0>,
				<DCC_READ 0x9731014 1 0>,
				<DCC_READ 0x9731204 1 0>,
				<DCC_READ 0x973120c 1 0>,
				<DCC_READ 0x9731214 1 0>,
				<DCC_READ 0x9731504 1 0>,
				<DCC_READ 0x973150c 1 0>,
				<DCC_READ 0x9731514 1 0>,
				<DCC_READ 0x9731604 1 0>,
				<DCC_READ 0x9738100 1 0>,
				<DCC_READ 0x973813c 1 0>,
				<DCC_READ 0x9738500 1 0>,
				<DCC_READ 0x973853c 1 0>,
				<DCC_READ 0x9738a04 1 0>,
				<DCC_READ 0x9738a18 1 0>,
				<DCC_READ 0x9738ea8 1 0>,
				<DCC_READ 0x9739044 1 0>,
				<DCC_READ 0x973904c 1 0>,
				<DCC_READ 0x9739054 1 0>,
				<DCC_READ 0x973905c 1 0>,
				<DCC_READ 0x973910c 2 0>,
				<DCC_READ 0x9739204 1 0>,
				<DCC_READ 0x973920c 1 0>,
				<DCC_READ 0x9739238 1 0>,
				<DCC_READ 0x9739240 1 0>,
				<DCC_READ 0x973926c 1 0>,
				<DCC_READ 0x9739394 1 0>,
				<DCC_READ 0x973939c 1 0>,
				<DCC_READ 0x9739704 1 0>,
				<DCC_READ 0x973970c 1 0>,
				<DCC_READ 0x9770868 1 0>,
				<DCC_READ 0x9770870 1 0>,
				<DCC_READ 0x9771004 1 0>,
				<DCC_READ 0x977100c 1 0>,
				<DCC_READ 0x9771014 1 0>,
				<DCC_READ 0x9771204 1 0>,
				<DCC_READ 0x977120c 1 0>,
				<DCC_READ 0x9771214 1 0>,
				<DCC_READ 0x9771504 1 0>,
				<DCC_READ 0x977150c 1 0>,
				<DCC_READ 0x9771514 1 0>,
				<DCC_READ 0x9771604 1 0>,
				<DCC_READ 0x9778100 1 0>,
				<DCC_READ 0x977813c 1 0>,
				<DCC_READ 0x9778500 1 0>,
				<DCC_READ 0x977853c 1 0>,
				<DCC_READ 0x9778a04 1 0>,
				<DCC_READ 0x9778a18 1 0>,
				<DCC_READ 0x9778ea8 1 0>,
				<DCC_READ 0x9779044 1 0>,
				<DCC_READ 0x977904c 1 0>,
				<DCC_READ 0x9779054 1 0>,
				<DCC_READ 0x977905c 1 0>,
				<DCC_READ 0x977910c 2 0>,
				<DCC_READ 0x9779204 1 0>,
				<DCC_READ 0x977920c 1 0>,
				<DCC_READ 0x9779238 1 0>,
				<DCC_READ 0x9779240 1 0>,
				<DCC_READ 0x977926c 1 0>,
				<DCC_READ 0x9779394 1 0>,
				<DCC_READ 0x977939c 1 0>,
				<DCC_READ 0x9779704 1 0>,
				<DCC_READ 0x977970c 1 0>,
				<DCC_READ 0x910d100 3 0>,
				<DCC_READ 0x914d100 3 0>,
				<DCC_READ 0x918d100 4 0>,
				<DCC_READ 0x91a5100 1 0>,
				<DCC_READ 0x91ad100 1 0>,
				<DCC_READ 0x610110 5 0>,
				<DCC_WRITE 0x06e0a00c 0x00600007 1>,
				<DCC_WRITE 0x06e0a01c 0x00136800 1>,
				<DCC_READ 0x06e0a014 1 1>,
				<DCC_WRITE 0x06e0a01c 0x00136810 1>,
				<DCC_READ 0x06e0a014 1 1>,
				<DCC_WRITE 0x06e0a01c 0x00136820 1>,
				<DCC_READ 0x06e0a014 1 1>,
				<DCC_WRITE 0x06e0a01c 0x00136830 1>,
				<DCC_READ 0x06e0a014 1 1>,
				<DCC_WRITE 0x06e0a01c 0x00136840 1>,
				<DCC_READ 0x06e0a014 1 1>,
				<DCC_WRITE 0x06e0a01c 0x00136850 1>,
				<DCC_READ 0x06e0a014 1 1>,
				<DCC_WRITE 0x06e0a01c 0x00136860 1>,
				<DCC_READ 0x06e0a014 1 1>,
				<DCC_WRITE 0x06e0a01c 0x00136870 1>,
				<DCC_READ 0x06e0a014 1 1>,
				<DCC_WRITE 0x06e0a01c 0x0003e9a0 1>,
				<DCC_WRITE 0x06e0a01c 0x001368a0 1>,
				<DCC_READ 0x06e0a014 1 1>,
				<DCC_WRITE 0x06e0a01c 0x0003c0a0 1>,
				<DCC_WRITE 0x06e0a01c 0x001368a0 1>,
				<DCC_READ 0x06e0a014 1 1>,
				<DCC_WRITE 0x06e0a01c 0x0003d1a0 1>,
				<DCC_WRITE 0x06e0a01c 0x001368a0 1>,
				<DCC_READ 0x06e0a014 1 1>,
				<DCC_WRITE 0x06e0a01c 0x0003d2a0 1>,
				<DCC_WRITE 0x06e0a01c 0x001368a0 1>,
				<DCC_READ 0x06e0a014 1 1>,
				<DCC_WRITE 0x06e0a01c 0x0003d5a0 1>,
				<DCC_WRITE 0x06e0a01c 0x001368a0 1>,
				<DCC_READ 0x06e0a014 1 1>,
				<DCC_WRITE 0x06e0a01c 0x0003d6a0 1>,
				<DCC_WRITE 0x06e0a01c 0x001368a0 1>,
				<DCC_READ 0x06e0a014 1 1>,
				<DCC_WRITE 0x06e0a01c 0x0003e8a0 1>,
				<DCC_WRITE 0x06e0a01c 0x001368a0 1>,
				<DCC_READ 0x06e0a014 1 1>,
				<DCC_WRITE 0x06e0a01c 0x0003eea0 1>,
				<DCC_WRITE 0x06e0a01c 0x001368a0 1>,
				<DCC_READ 0x06e0a014 1 1>,
				<DCC_WRITE 0x06e0a01c 0x0003b1a0 1>,
				<DCC_WRITE 0x06e0a01c 0x001368a0 1>,
				<DCC_READ 0x06e0a014 1 1>,
				<DCC_WRITE 0x06e0a01c 0x0003b2a0 1>,
				<DCC_WRITE 0x06e0a01c 0x001368a0 1>,
				<DCC_READ 0x06e0a014 1 1>,
				<DCC_WRITE 0x06e0a01c 0x0003b5a0 1>,
				<DCC_WRITE 0x06e0a01c 0x001368a0 1>,
				<DCC_READ 0x06e0a014 1 1>,
				<DCC_WRITE 0x06e0a01c 0x0003b6a0 1>,
				<DCC_WRITE 0x06e0a01c 0x001368a0 1>,
				<DCC_READ 0x06e0a014 1 1>,
				<DCC_WRITE 0x06e0a01c 0x0003c2a0 1>,
				<DCC_WRITE 0x06e0a01c 0x001368a0 1>,
				<DCC_READ 0x06e0a014 1 1>,
				<DCC_WRITE 0x06e0a01c 0x0003c5a0 1>,
				<DCC_WRITE 0x06e0a01c 0x001368a0 1>,
				<DCC_READ 0x06e0a014 1 1>,
				<DCC_WRITE 0x06e0a01c 0x0003c6a0 1>,
				<DCC_WRITE 0x06e0a01c 0x001368a0 1>,
				<DCC_READ 0x06e0a014 1 1>,
				<DCC_WRITE 0x06e0a014 0x0002000c 1>,
				<DCC_WRITE 0x06e0a01c 0x000368b0 1>,
				<DCC_WRITE 0x06e0a01c 0x00000ba8 1>,
				<DCC_WRITE 0x06e0a01c 0x0013b6a0 1>,
				<DCC_WRITE 0x06e0a01c 0x00f1e000 1>,
				<DCC_WRITE 0x06e0a008 0x00000007 1>,
				<DCC_READ 0x09067e00 124 0>;
		};

		link_list3 {
			qcom,curr-link-list = <3>;
			qcom,data-sink = "sram";

			qcom,link-list = <DCC_READ 0x18200400 1 0>,
				<DCC_READ 0x18200404 1 0>,
				<DCC_READ 0x18200408 1 0>,
				<DCC_READ 0x18200038 1 0>,
				<DCC_READ 0x18200040 1 0>,
				<DCC_READ 0x18200048 1 0>,
				<DCC_READ 0x18220038 1 0>,
				<DCC_READ 0x18220040 1 0>,
				<DCC_READ 0x182200d0 1 0>,
				<DCC_READ 0x18200030 1 0>,
				<DCC_READ 0x18200010 1 0>,
				<DCC_READ 0x1822000c 1 0>,
				<DCC_READ 0x18220d14 1 0>,
				<DCC_READ 0x18220fb4 1 0>,
				<DCC_READ 0x18221254 1 0>,
				<DCC_READ 0x182214f4 1 0>,
				<DCC_READ 0x18221794 1 0>,
				<DCC_READ 0x18221a34 1 0>,
				<DCC_READ 0x18221cd4 1 0>,
				<DCC_READ 0x18221f74 1 0>,
				<DCC_READ 0x18220d18 1 0>,
				<DCC_READ 0x18220fb8 1 0>,
				<DCC_READ 0x18221258 1 0>,
				<DCC_READ 0x182214f8 1 0>,
				<DCC_READ 0x18221798 1 0>,
				<DCC_READ 0x18221a38 1 0>,
				<DCC_READ 0x18221cd8 1 0>,
				<DCC_READ 0x18221f78 1 0>,
				<DCC_READ 0x18220d00 1 0>,
				<DCC_READ 0x18220d04 1 0>,
				<DCC_READ 0x18220d1c 1 0>,
				<DCC_READ 0x18220fbc 1 0>,
				<DCC_READ 0x1822125c 1 0>,
				<DCC_READ 0x182214fc 1 0>,
				<DCC_READ 0x1822179c 1 0>,
				<DCC_READ 0x18221a3c 1 0>,
				<DCC_READ 0x18221cdc 1 0>,
				<DCC_READ 0x18221f7c 1 0>,
				<DCC_READ 0x18221274 1 0>,
				<DCC_READ 0x18221288 1 0>,
				<DCC_READ 0x1822129c 1 0>,
				<DCC_READ 0x182212b0 1 0>,
				<DCC_READ 0x182212c4 1 0>,
				<DCC_READ 0x182212d8 1 0>,
				<DCC_READ 0x182212ec 1 0>,
				<DCC_READ 0x18221300 1 0>,
				<DCC_READ 0x18221314 1 0>,
				<DCC_READ 0x18221328 1 0>,
				<DCC_READ 0x1822133c 1 0>,
				<DCC_READ 0x18221350 1 0>,
				<DCC_READ 0x18221364 1 0>,
				<DCC_READ 0x18221378 1 0>,
				<DCC_READ 0x1822138c 1 0>,
				<DCC_READ 0x182213a0 1 0>,
				<DCC_READ 0x18221514 1 0>,
				<DCC_READ 0x18221528 1 0>,
				<DCC_READ 0x1822153c 1 0>,
				<DCC_READ 0x18221550 1 0>,
				<DCC_READ 0x18221564 1 0>,
				<DCC_READ 0x18221578 1 0>,
				<DCC_READ 0x1822158c 1 0>,
				<DCC_READ 0x182215a0 1 0>,
				<DCC_READ 0x182215b4 1 0>,
				<DCC_READ 0x182215c8 1 0>,
				<DCC_READ 0x182215dc 1 0>,
				<DCC_READ 0x182215f0 1 0>,
				<DCC_READ 0x18221604 1 0>,
				<DCC_READ 0x18221618 1 0>,
				<DCC_READ 0x1822162c 1 0>,
				<DCC_READ 0x18221640 1 0>,
				<DCC_READ 0x182217b4 1 0>,
				<DCC_READ 0x182217c8 1 0>,
				<DCC_READ 0x182217dc 1 0>,
				<DCC_READ 0x182217f0 1 0>,
				<DCC_READ 0x18221804 1 0>,
				<DCC_READ 0x18221818 1 0>,
				<DCC_READ 0x1822182c 1 0>,
				<DCC_READ 0x18221840 1 0>,
				<DCC_READ 0x18221854 1 0>,
				<DCC_READ 0x18221868 1 0>,
				<DCC_READ 0x1822187c 1 0>,
				<DCC_READ 0x18221890 1 0>,
				<DCC_READ 0x182218a4 1 0>,
				<DCC_READ 0x182218b8 1 0>,
				<DCC_READ 0x182218cc 1 0>,
				<DCC_READ 0x182218e0 1 0>,
				<DCC_READ 0x18221a54 1 0>,
				<DCC_READ 0x18221a68 1 0>,
				<DCC_READ 0x18221a7c 1 0>,
				<DCC_READ 0x18221a90 1 0>,
				<DCC_READ 0x18221aa4 1 0>,
				<DCC_READ 0x18221ab8 1 0>,
				<DCC_READ 0x18221acc 1 0>,
				<DCC_READ 0x18221ae0 1 0>,
				<DCC_READ 0x18221af4 1 0>,
				<DCC_READ 0x18221b08 1 0>,
				<DCC_READ 0x18221b1c 1 0>,
				<DCC_READ 0x18221b30 1 0>,
				<DCC_READ 0x18221b44 1 0>,
				<DCC_READ 0x18221b58 1 0>,
				<DCC_READ 0x18221b6c 1 0>,
				<DCC_READ 0x18221b80 1 0>,
				<DCC_READ 0x18221cf4 1 0>,
				<DCC_READ 0x18221d08 1 0>,
				<DCC_READ 0x18221d1c 1 0>,
				<DCC_READ 0x18221d30 1 0>,
				<DCC_READ 0x18221d44 1 0>,
				<DCC_READ 0x18221d58 1 0>,
				<DCC_READ 0x18221d6c 1 0>,
				<DCC_READ 0x18221d80 1 0>,
				<DCC_READ 0x18221d94 1 0>,
				<DCC_READ 0x18221da8 1 0>,
				<DCC_READ 0x18221dbc 1 0>,
				<DCC_READ 0x18221dd0 1 0>,
				<DCC_READ 0x18221de4 1 0>,
				<DCC_READ 0x18221df8 1 0>,
				<DCC_READ 0x18221e0c 1 0>,
				<DCC_READ 0x18221e20 1 0>,
				<DCC_READ 0x18221f94 1 0>,
				<DCC_READ 0x18221fa8 1 0>,
				<DCC_READ 0x18221fbc 1 0>,
				<DCC_READ 0x18221fd0 1 0>,
				<DCC_READ 0x18221fe4 1 0>,
				<DCC_READ 0x18221ff8 1 0>,
				<DCC_READ 0x1822200c 1 0>,
				<DCC_READ 0x18222020 1 0>,
				<DCC_READ 0x18222034 1 0>,
				<DCC_READ 0x18222048 1 0>,
				<DCC_READ 0x1822205c 1 0>,
				<DCC_READ 0x18222070 1 0>,
				<DCC_READ 0x18222084 1 0>,
				<DCC_READ 0x18222098 1 0>,
				<DCC_READ 0x182220ac 1 0>,
				<DCC_READ 0x182220c0 1 0>,
				<DCC_READ 0x18221278 1 0>,
				<DCC_READ 0x1822128c 1 0>,
				<DCC_READ 0x182212a0 1 0>,
				<DCC_READ 0x182212b4 1 0>,
				<DCC_READ 0x182212c8 1 0>,
				<DCC_READ 0x182212dc 1 0>,
				<DCC_READ 0x182212f0 1 0>,
				<DCC_READ 0x18221304 1 0>,
				<DCC_READ 0x18221318 1 0>,
				<DCC_READ 0x1822132c 1 0>,
				<DCC_READ 0x18221340 1 0>,
				<DCC_READ 0x18221354 1 0>,
				<DCC_READ 0x18221368 1 0>,
				<DCC_READ 0x1822137c 1 0>,
				<DCC_READ 0x18221390 1 0>,
				<DCC_READ 0x182213a4 1 0>,
				<DCC_READ 0x18221518 1 0>,
				<DCC_READ 0x1822152c 1 0>,
				<DCC_READ 0x18221540 1 0>,
				<DCC_READ 0x18221554 1 0>,
				<DCC_READ 0x18221568 1 0>,
				<DCC_READ 0x1822157c 1 0>,
				<DCC_READ 0x18221590 1 0>,
				<DCC_READ 0x182215a4 1 0>,
				<DCC_READ 0x182215b8 1 0>,
				<DCC_READ 0x182215cc 1 0>,
				<DCC_READ 0x182215e0 1 0>,
				<DCC_READ 0x182215f4 1 0>,
				<DCC_READ 0x18221608 1 0>,
				<DCC_READ 0x1822161c 1 0>,
				<DCC_READ 0x18221630 1 0>,
				<DCC_READ 0x18221644 1 0>,
				<DCC_READ 0x182217b8 1 0>,
				<DCC_READ 0x182217cc 1 0>,
				<DCC_READ 0x182217e0 1 0>,
				<DCC_READ 0x182217f4 1 0>,
				<DCC_READ 0x18221808 1 0>,
				<DCC_READ 0x1822181c 1 0>,
				<DCC_READ 0x18221830 1 0>,
				<DCC_READ 0x18221844 1 0>,
				<DCC_READ 0x18221858 1 0>,
				<DCC_READ 0x1822186c 1 0>,
				<DCC_READ 0x18221880 1 0>,
				<DCC_READ 0x18221894 1 0>,
				<DCC_READ 0x182218a8 1 0>,
				<DCC_READ 0x182218bc 1 0>,
				<DCC_READ 0x182218d0 1 0>,
				<DCC_READ 0x182218e4 1 0>,
				<DCC_READ 0x18221a58 1 0>,
				<DCC_READ 0x18221a6c 1 0>,
				<DCC_READ 0x18221a80 1 0>,
				<DCC_READ 0x18221a94 1 0>,
				<DCC_READ 0x18221aa8 1 0>,
				<DCC_READ 0x18221abc 1 0>,
				<DCC_READ 0x18221ad0 1 0>,
				<DCC_READ 0x18221ae4 1 0>,
				<DCC_READ 0x18221af8 1 0>,
				<DCC_READ 0x18221b0c 1 0>,
				<DCC_READ 0x18221b20 1 0>,
				<DCC_READ 0x18221b34 1 0>,
				<DCC_READ 0x18221b48 1 0>,
				<DCC_READ 0x18221b5c 1 0>,
				<DCC_READ 0x18221b70 1 0>,
				<DCC_READ 0x18221b84 1 0>,
				<DCC_READ 0x18221cf8 1 0>,
				<DCC_READ 0x18221d0c 1 0>,
				<DCC_READ 0x18221d20 1 0>,
				<DCC_READ 0x18221d34 1 0>,
				<DCC_READ 0x18221d48 1 0>,
				<DCC_READ 0x18221d5c 1 0>,
				<DCC_READ 0x18221d70 1 0>,
				<DCC_READ 0x18221d84 1 0>,
				<DCC_READ 0x18221d98 1 0>,
				<DCC_READ 0x18221dac 1 0>,
				<DCC_READ 0x18221dc0 1 0>,
				<DCC_READ 0x18221dd4 1 0>,
				<DCC_READ 0x18221de8 1 0>,
				<DCC_READ 0x18221dfc 1 0>,
				<DCC_READ 0x18221e10 1 0>,
				<DCC_READ 0x18221e24 1 0>,
				<DCC_READ 0x18221f98 1 0>,
				<DCC_READ 0x18221fac 1 0>,
				<DCC_READ 0x18221fc0 1 0>,
				<DCC_READ 0x18221fd4 1 0>,
				<DCC_READ 0x18221fe8 1 0>,
				<DCC_READ 0x18221ffc 1 0>,
				<DCC_READ 0x18222010 1 0>,
				<DCC_READ 0x18222024 1 0>,
				<DCC_READ 0x18222038 1 0>,
				<DCC_READ 0x1822204c 1 0>,
				<DCC_READ 0x18222060 1 0>,
				<DCC_READ 0x18222074 1 0>,
				<DCC_READ 0x18222088 1 0>,
				<DCC_READ 0x1822209c 1 0>,
				<DCC_READ 0x182220b0 1 0>,
				<DCC_READ 0x182220c4 1 0>;
		};
	};

	mem_dump {
		compatible = "qcom,mem-dump";
		memory-region = <&dump_mem>;

		static_mem_dump {
			qcom,static-mem-dump;

			c0_context {
				qcom,dump-size = <0x800>;
				qcom,dump-id = <0x0>;
			};

			c100_context {
				qcom,dump-size = <0x800>;
				qcom,dump-id = <0x1>;
			};

			c200_context {
				qcom,dump-size = <0x800>;
				qcom,dump-id = <0x2>;
			};

			c300_context {
				qcom,dump-size = <0x800>;
				qcom,dump-id = <0x3>;
			};

			c400_context {
				qcom,dump-size = <0x800>;
				qcom,dump-id = <0x4>;
			};

			c500_context {
				qcom,dump-size = <0x800>;
				qcom,dump-id = <0x5>;
			};

			c600_context {
				qcom,dump-size = <0x800>;
				qcom,dump-id = <0x6>;
			};

			c700_context {
				qcom,dump-size = <0x800>;
				qcom,dump-id = <0x7>;
			};

			c0_scandump {
				qcom,dump-size = <0x10100>;
				qcom,dump-id = <0x130>;
			};

			c100_scandump {
				qcom,dump-size = <0x10100>;
				qcom,dump-id = <0x131>;
			};

			c200_scandump {
				qcom,dump-size = <0x10100>;
				qcom,dump-id = <0x132>;
			};

			c300_scandump {
				qcom,dump-size = <0x10100>;
				qcom,dump-id = <0x133>;
			};

			c400_scandump: c400_scandump {
				qcom,dump-size = <0x1a4c0>;
				qcom,dump-id = <0x134>;
			};

			c500_scandump: c500_scandump {
				qcom,dump-size = <0x1a4c0>;
				qcom,dump-id = <0x135>;
			};

			c600_scandump: c600_scandump {
				qcom,dump-size = <0x1a4c0>;
				qcom,dump-id = <0x136>;
			};

			c700_scandump: c700_scandump {
				qcom,dump-size = <0x1a4c0>;
				qcom,dump-id = <0x137>;
			};

			gemnoc {
				qcom,dump-size = <0x100000>;
				qcom,dump-id = <0x162>;
			};

			mhm_scan {
				qcom,dump-size = <0x20000>;
				qcom,dump-id = <0x161>;
			};

			rpmh {
				qcom,dump-size = <0x2000000>;
				qcom,dump-id = <0xec>;
			};

			rpm_sw {
				qcom,dump-size = <0x28000>;
				qcom,dump-id = <0xea>;
			};

			pmic {
				qcom,dump-size = <0x200000>;
				qcom,dump-id = <0xe4>;
			};

			fcm {
				qcom,dump-size = <0x8400>;
				qcom,dump-id = <0xee>;
			};

			etf_swao {
				qcom,dump-size = <0x10000>;
				qcom,dump-id = <0xf1>;
			};

			etr_reg {
				qcom,dump-size = <0x1000>;
				qcom,dump-id = <0x100>;
			};

			etfswao_reg {
				qcom,dump-size = <0x1000>;
				qcom,dump-id = <0x102>;
			};

			misc_data {
				qcom,dump-size = <0x1000>;
				qcom,dump-id = <0xe8>;
			};

			etf_slpi {
				qcom,dump-size = <0x4000>;
				qcom,dump-id = <0xf3>;
			};

			etfslpi_reg {
				qcom,dump-size = <0x1000>;
				qcom,dump-id = <0x103>;
			};

			etf_lpass {
				qcom,dump-size = <0x4000>;
				qcom,dump-id = <0xf4>;
			};

			etflpass_reg {
				qcom,dump-size = <0x1000>;
				qcom,dump-id = <0x104>;
			};

		};

		dynamic_mem_dump {
			qcom,dynamic-mem-dump;

			cpuss_reg {
				cpuss_reg {
					qcom,dump-size = <0x30000>;
					qcom,dump-id = <0xef>;
				};
			};

			l1 {
				l1_icache0 {
					qcom,dump-size = <0x10900>;
					qcom,dump-id = <0x60>;
				};

				l1_icache100 {
					qcom,dump-size = <0x10900>;
					qcom,dump-id = <0x61>;
				};

				l1_icache200 {
					qcom,dump-size = <0x10900>;
					qcom,dump-id = <0x62>;
				};

				l1_icache300 {
					qcom,dump-size = <0x10900>;
					qcom,dump-id = <0x63>;
				};

				l1_icache400 {
					qcom,dump-size = <0x15100>;
					qcom,dump-id = <0x64>;
				};

				l1_icache500 {
					qcom,dump-size = <0x15100>;
					qcom,dump-id = <0x65>;
				};

				l1_icache600 {
					qcom,dump-size = <0x15100>;
					qcom,dump-id = <0x66>;
				};

				l1_icache700 {
					qcom,dump-size = <0x32100>;
					qcom,dump-id = <0x67>;
				};

				l1_dcache0 {
					qcom,dump-size = <0x9100>;
					qcom,dump-id = <0x80>;
				};

				l1_dcache100 {
					qcom,dump-size = <0x9100>;
					qcom,dump-id = <0x81>;
				};

				l1_dcache200 {
					qcom,dump-size = <0x9100>;
					qcom,dump-id = <0x82>;
				};

				l1_dcache300 {
					qcom,dump-size = <0x9100>;
					qcom,dump-id = <0x83>;
				};

				l1_dcache400 {
					qcom,dump-size = <0x9100>;
					qcom,dump-id = <0x84>;
				};

				l1_dcache500 {
					qcom,dump-size = <0x9100>;
					qcom,dump-id = <0x85>;
				};

				l1_dcache600 {
					qcom,dump-size = <0x9100>;
					qcom,dump-id = <0x86>;
				};

				l1_dcache700 {
					qcom,dump-size = <0x12100>;
					qcom,dump-id = <0x87>;
				};

				l1_itlb400 {
					qcom,dump-size = <0x300>;
					qcom,dump-id = <0x24>;
				};

				l1_itlb500 {
					qcom,dump-size = <0x300>;
					qcom,dump-id = <0x25>;
				};

				l1_itlb600 {
					qcom,dump-size = <0x300>;
					qcom,dump-id = <0x26>;
				};

				l1_itlb700 {
					qcom,dump-size = <0x400>;
					qcom,dump-id = <0x27>;
				};

				l1_dtlb400 {
					qcom,dump-size = <0x300>;
					qcom,dump-id = <0x44>;
				};

				l1_dtlb500 {
					qcom,dump-size = <0x300>;
					qcom,dump-id = <0x45>;
				};

				l1_dtlb600 {
					qcom,dump-size = <0x300>;
					qcom,dump-id = <0x46>;
				};

				l1_dtlb700 {
					qcom,dump-size = <0x3a0>;
					qcom,dump-id = <0x47>;
				};

			};

			l2 {
				l2_cache400 {
					qcom,dump-size = <0x90100>;
					qcom,dump-id = <0xc4>;
				};

				l2_cache500 {
					qcom,dump-size = <0x90100>;
					qcom,dump-id = <0xc5>;
				};

				l2_cache600 {
					qcom,dump-size = <0x90100>;
					qcom,dump-id = <0xc6>;
				};

				l2_cache700 {
					qcom,dump-size = <0x120100>;
					qcom,dump-id = <0xc7>;
				};

				l2_tlb0 {
					qcom,dump-size = <0x5b00>;
					qcom,dump-id = <0x120>;
				};

				l2_tlb100 {
					qcom,dump-size = <0x5b00>;
					qcom,dump-id = <0x121>;
				};

				l2_tlb200 {
					qcom,dump-size = <0x5b00>;
					qcom,dump-id = <0x122>;
				};

				l2_tlb300 {
					qcom,dump-size = <0x5b00>;
					qcom,dump-id = <0x123>;
				};

				l2_tlb400 {
					qcom,dump-size = <0x6100>;
					qcom,dump-id = <0x124>;
				};

				l2_tlb500 {
					qcom,dump-size = <0x6100>;
					qcom,dump-id = <0x125>;
				};

				l2_tlb600 {
					qcom,dump-size = <0x6100>;
					qcom,dump-id = <0x126>;
				};

				l2_tlb700 {
					qcom,dump-size = <0xc100>;
					qcom,dump-id = <0x127>;
				};

			};

			LLCC_1 {
				llcc_1_dcache {
					qcom,dump-size = <0x1141c0>;
					qcom,dump-id = <0x140>;
				};
			};

			LLCC_2 {
				llcc_2_dcache {
					qcom,dump-size = <0x1141c0>;
					qcom,dump-id = <0x141>;
				};
			};

			LLCC_3 {
				llcc_3_dcache {
					qcom,dump-size = <0x1141c0>;
					qcom,dump-id = <0x142>;
				};
			};

			LLCC_4 {
				llcc_4_dcache {
					qcom,dump-size = <0x1141c0>;
					qcom,dump-id = <0x143>;
				};
			};
		};
	};
};
